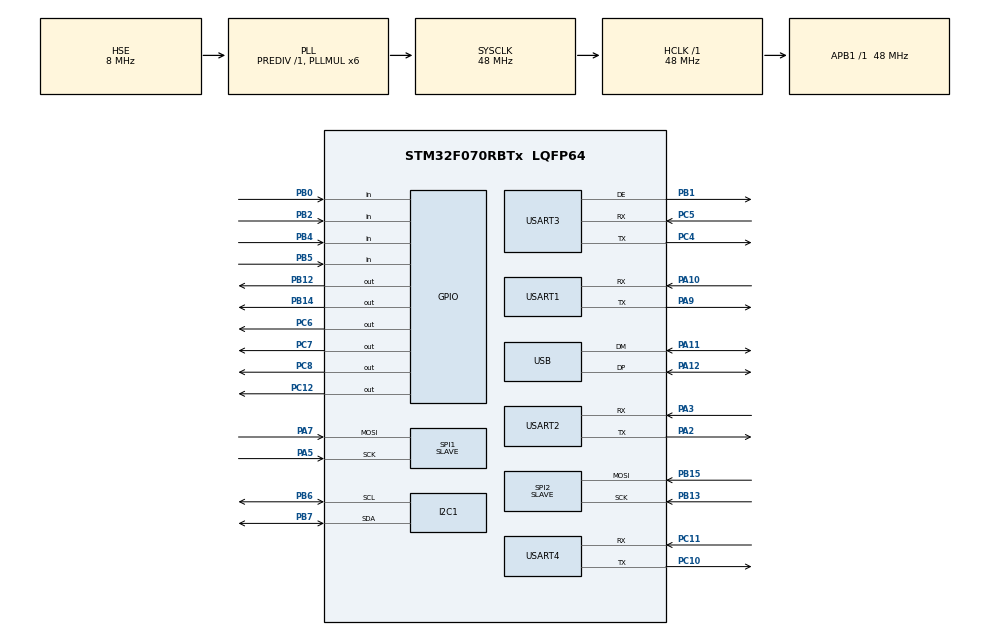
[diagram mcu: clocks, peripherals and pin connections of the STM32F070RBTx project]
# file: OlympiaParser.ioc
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Mcu.Family=STM32F0
Mcu.Name=STM32F070RBTx
Mcu.Package=LQFP64
NVIC.USB_IRQn=true\:0\:0\:false\:false\:true\:false\:true\:true
PA10.Mode=Asynchronous
PA10.Signal=USART1_RX
PA11.Mode=Device
PA11.Signal=USB_DM
PA12.Mode=Device
PA12.Signal=USB_DP
PA13.Mode=Serial_Wire
PA13.Signal=SYS_SWDIO
PA14.Mode=Serial_Wire
PA14.Signal=SYS_SWCLK
PA2.Mode=Asynchronous
PA2.Signal=USART2_TX
PA3.Mode=Asynchronous
PA3.Signal=USART2_RX
PA5.Mode=RX_Only_Simplex_Unidirect_Slave
PA5.Signal=SPI1_SCK
PA7.Mode=RX_Only_Simplex_Unidirect_Slave
PA7.Signal=SPI1_MOSI
PA9.Mode=Asynchronous
PA9.Signal=USART1_TX
PB0.Signal=GPIO_Input
PB1.Mode=Hardware Flow Control (RS485)
PB1.Signal=USART3_DE
PB12.Signal=GPIO_Output
PB13.Mode=RX_Only_Simplex_Unidirect_Slave
PB13.Signal=SPI2_SCK
PB14.Signal=GPIO_Output
PB15.Mode=RX_Only_Simplex_Unidirect_Slave
PB15.Signal=SPI2_MOSI
PB2.Signal=GPIO_Input
PB4.Signal=GPIO_Input
PB5.Signal=GPIO_Input
PB6.Mode=I2C
PB6.Signal=I2C1_SCL
PB7.Mode=I2C
PB7.Signal=I2C1_SDA
PC10.Mode=Asynchronous
PC10.Signal=USART4_TX
PC11.Mode=Asynchronous
PC11.Signal=USART4_RX
PC12.Signal=GPIO_Output
PC4.Mode=Asynchronous
PC4.Signal=USART3_TX
PC5.Mode=Asynchronous
PC5.Signal=USART3_RX
PC6.Signal=GPIO_Output
PC7.Signal=GPIO_Output
PC8.Signal=GPIO_Output
PF0-OSC_IN.Mode=HSE-External-Oscillator
PF0-OSC_IN.Signal=RCC_OSC_IN
PF1-OSC_OUT.Mode=HSE-External-Oscillator
PF1-OSC_OUT.Signal=RCC_OSC_OUT
ProjectManager.HeapSize=0x200
ProjectManager.StackSize=0x400
ProjectManager.TargetToolchain=EWARM V8.32
RCC.AHBFreq_Value=48000000
RCC.APB1Freq_Value=48000000
RCC.APB1TimFreq_Value=48000000
RCC.HCLKFreq_Value=48000000
RCC.PLLMUL=RCC_PLL_MUL6
RCC.SYSCLKFreq_VALUE=48000000
RCC.SYSCLKSource=RCC_SYSCLKSOURCE_PLLCLK
SPI1.Direction=SPI_DIRECTION_2LINES_RXONLY
SPI1.Mode=SPI_MODE_SLAVE
SPI1.VirtualType=VM_SLAVE
SPI2.Direction=SPI_DIRECTION_2LINES_RXONLY
SPI2.Mode=SPI_MODE_SLAVE
SPI2.VirtualType=VM_SLAVE
USART1.VirtualMode-Asynchronous=VM_ASYNC
USART2.VirtualMode-Asynchronous=VM_ASYNC
USART3.VirtualMode-Asynchronous=VM_ASYNC
USART3.VirtualMode-Hardware\ Flow\ Control\ (RS485)=VM_ASYNC
USART4.VirtualMode-Asynchronous=VM_ASYNC
USB_DEVICE.CLASS_NAME_FS=CDC
USB_DEVICE.VirtualMode=Cdc
USB_DEVICE.VirtualModeFS=Cdc_FS
VP_USB_DEVICE_VS_USB_DEVICE_CDC_FS.Mode=CDC_FS
board=custom

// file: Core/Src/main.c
/* USER CODE BEGIN Header */
/**
  ******************************************************************************
  * @file           : main.c
  * @brief          : Main program body
  ******************************************************************************
  * @attention
  *
  * Copyright (c) 2022 STMicroelectronics.
  * All rights reserved.
  *
  * This software is licensed under terms that can be found in the LICENSE file
  * in the root directory of this software component.
  * If no LICENSE file comes with this software, it is provided AS-IS.
  *
  ******************************************************************************
  */
/* USER CODE END Header */
#include "main.h"
#include "i2c.h"
#include "spi.h"
#include "usart.h"
#include "usb_device.h"
#include "gpio.h"

/* USER CODE BEGIN Includes */
#include "comm_usb.h"
#include "string.h"
#include "stdbool.h"
/* USER CODE END Includes */

/* USER CODE BEGIN PTD */
uint8_t tx_buffer[200] = "Hello World";
static bool packet_sent;
static uint8_t send_packet;
/* USER CODE END PTD */

/* USER CODE BEGIN PD */
#define _DEBUG
/* USER CODE END PD */

void SystemClock_Config(void);

int main(void)
{

  /* MCU Configuration--------------------------------------------------------*/

  /* Reset of all peripherals, Initializes the Flash interface and the Systick. */
  HAL_Init();

  /* Configure the system clock */
  SystemClock_Config();

  /* Initialize all configured peripherals */
  MX_GPIO_Init();
  MX_I2C1_Init();
  MX_SPI1_Init();
  MX_SPI2_Init();
  MX_USART1_UART_Init();
  MX_USART2_UART_Init();
  MX_USART3_UART_Init();
  MX_USART4_UART_Init();
  MX_USB_DEVICE_Init();
  COMM_USB_Init();

  /* USER CODE BEGIN 2 */
  #ifdef _DEBUG
  RCC->APB2ENR |= RCC_APB2ENR_DBGMCUEN; // enable MCU debug module clock
  HAL_DBGMCU_EnableDBGStandbyMode();
  HAL_DBGMCU_EnableDBGStopMode();
  DBGMCU->APB1FZ |= DBGMCU_APB1_FZ_DBG_TIM3_STOP; // enable timer 3 stop
  #endif

  /* USER CODE END 2 */

  /* Infinite loop */
  while (1)
  {
    if (send_packet==1)
    {
      send_packet = 0;
      packet_sent = COMM_USB_send_packet(tx_buffer, strlen((char *)tx_buffer));
    }
  }
}

void SystemClock_Config(void)
{
  RCC_OscInitTypeDef RCC_OscInitStruct = {0};
  RCC_ClkInitTypeDef RCC_ClkInitStruct = {0};
  RCC_PeriphCLKInitTypeDef PeriphClkInit = {0};

  /** Initializes the RCC Oscillators according to the specified parameters
  * in the RCC_OscInitTypeDef structure.
  */
  RCC_OscInitStruct.OscillatorType = RCC_OSCILLATORTYPE_HSI|RCC_OSCILLATORTYPE_HSE;
  RCC_OscInitStruct.HSEState = RCC_HSE_ON;
  RCC_OscInitStruct.HSIState = RCC_HSI_ON;
  RCC_OscInitStruct.HSICalibrationValue = RCC_HSICALIBRATION_DEFAULT;
  RCC_OscInitStruct.PLL.PLLState = RCC_PLL_ON;
  RCC_OscInitStruct.PLL.PLLSource = RCC_PLLSOURCE_HSE;
  RCC_OscInitStruct.PLL.PLLMUL = RCC_PLL_MUL6;
  RCC_OscInitStruct.PLL.PREDIV = RCC_PREDIV_DIV1;
  if (HAL_RCC_OscConfig(&RCC_OscInitStruct) != HAL_OK)
  {
    Error_Handler();
  }

  /** Initializes the CPU, AHB and APB buses clocks
  */
  RCC_ClkInitStruct.ClockType = RCC_CLOCKTYPE_HCLK|RCC_CLOCKTYPE_SYSCLK
                              |RCC_CLOCKTYPE_PCLK1;
  RCC_ClkInitStruct.SYSCLKSource = RCC_SYSCLKSOURCE_PLLCLK;
  RCC_ClkInitStruct.AHBCLKDivider = RCC_SYSCLK_DIV1;
  RCC_ClkInitStruct.APB1CLKDivider = RCC_HCLK_DIV1;

  if (HAL_RCC_ClockConfig(&RCC_ClkInitStruct, FLASH_LATENCY_1) != HAL_OK)
  {
    Error_Handler();
  }
  PeriphClkInit.PeriphClockSelection = RCC_PERIPHCLK_USB|RCC_PERIPHCLK_USART1
                              |RCC_PERIPHCLK_I2C1;
  PeriphClkInit.Usart1ClockSelection = RCC_USART1CLKSOURCE_PCLK1;
  PeriphClkInit.I2c1ClockSelection = RCC_I2C1CLKSOURCE_HSI;
  PeriphClkInit.UsbClockSelection = RCC_USBCLKSOURCE_PLL;

  if (HAL_RCCEx_PeriphCLKConfig(&PeriphClkInit) != HAL_OK)
  {
    Error_Handler();
  }
}

void Error_Handler(void)
{
  __disable_irq();
  while (1)
  {
  }
}
